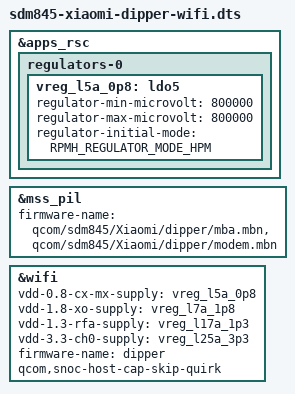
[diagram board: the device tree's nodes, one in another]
// SPDX-License-Identifier: GPL-2.0
#include "sdm845-xiaomi-dipper.dts"

/* Values from the downstream dipper device tree. */
&apps_rsc {
	regulators-0 {
		vreg_l5a_0p8: ldo5 {
			regulator-min-microvolt = <800000>;
			regulator-max-microvolt = <800000>;
			regulator-initial-mode = <RPMH_REGULATOR_MODE_HPM>;
		};
	};
};

&mss_pil {
	firmware-name = "qcom/sdm845/Xiaomi/dipper/mba.mbn",
			"qcom/sdm845/Xiaomi/dipper/modem.mbn";
	status = "okay";
};

&wifi {
	vdd-0.8-cx-mx-supply = <&vreg_l5a_0p8>;
	vdd-1.8-xo-supply = <&vreg_l7a_1p8>;
	vdd-1.3-rfa-supply = <&vreg_l17a_1p3>;
	vdd-3.3-ch0-supply = <&vreg_l25a_3p3>;
	firmware-name = "dipper";
	qcom,snoc-host-cap-skip-quirk;
	status = "okay";
};
